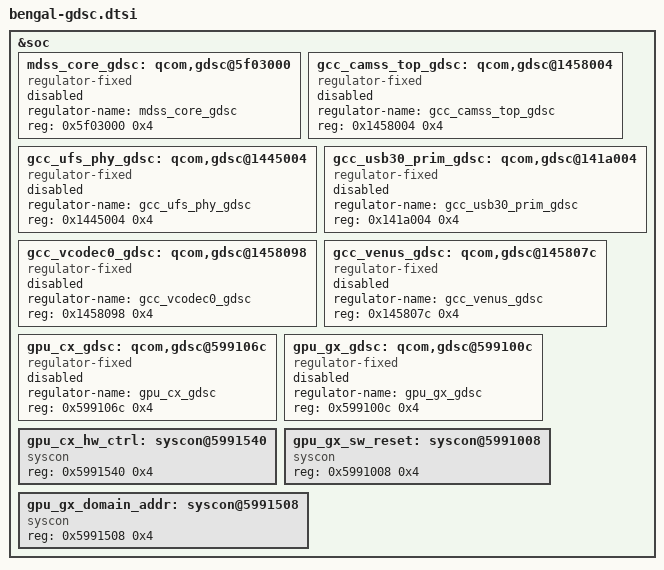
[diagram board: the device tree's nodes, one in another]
&soc {
	/* GDSCs in DISPCC*/
	mdss_core_gdsc: qcom,gdsc@5f03000 {
		compatible = "regulator-fixed";
		regulator-name = "mdss_core_gdsc";
		reg = <0x5f03000 0x4>;
		status = "disabled";
	};

	/* GDSCs in GCC*/
	gcc_camss_top_gdsc: qcom,gdsc@1458004 {
		compatible = "regulator-fixed";
		regulator-name = "gcc_camss_top_gdsc";
		reg = <0x1458004 0x4>;
		status = "disabled";
	};

	gcc_ufs_phy_gdsc: qcom,gdsc@1445004 {
		compatible = "regulator-fixed";
		regulator-name = "gcc_ufs_phy_gdsc";
		reg = <0x1445004 0x4>;
		status = "disabled";
	};

	gcc_usb30_prim_gdsc: qcom,gdsc@141a004 {
		compatible = "regulator-fixed";
		regulator-name = "gcc_usb30_prim_gdsc";
		reg = <0x141a004 0x4>;
		status = "disabled";
	};

	gcc_vcodec0_gdsc: qcom,gdsc@1458098 {
		compatible = "regulator-fixed";
		regulator-name = "gcc_vcodec0_gdsc";
		reg = <0x1458098 0x4>;
		status = "disabled";
	};

	gcc_venus_gdsc: qcom,gdsc@145807c {
		compatible = "regulator-fixed";
		regulator-name = "gcc_venus_gdsc";
		reg = <0x145807c 0x4>;
		status = "disabled";
	};

	/* GDSCs in GPUCC*/
	gpu_cx_gdsc: qcom,gdsc@599106c {
		compatible = "regulator-fixed";
		regulator-name = "gpu_cx_gdsc";
		reg = <0x599106c 0x4>;
		status = "disabled";
	};

	gpu_gx_gdsc: qcom,gdsc@599100c {
		compatible = "regulator-fixed";
		regulator-name = "gpu_gx_gdsc";
		reg = <0x599100c 0x4>;
		status = "disabled";
	};

	gpu_cx_hw_ctrl: syscon@5991540 {
		compatible = "syscon";
		reg = <0x5991540 0x4>;
	};

	gpu_gx_sw_reset: syscon@5991008 {
		compatible = "syscon";
		reg = <0x5991008 0x4>;
	};

	gpu_gx_domain_addr: syscon@5991508 {
		compatible = "syscon";
		reg = <0x5991508 0x4>;
	};
};
